# ESP32S31_RADIO register map
Vendor: Espressif; Series: ESP32-S31; File version: 3.52
Registers are 32-bit, read-write, no defined reset value unless marked. A register's access mark holds for its fields unless they carry their own. Offsets are from the block's base; [hi:lo] are bit positions; {n}, {i} and the like mark numbered series.

## PHY_BTAGC_RECOVERED — Sparse BTAGC words absent from the public platform PAC.
Base 0x20102800
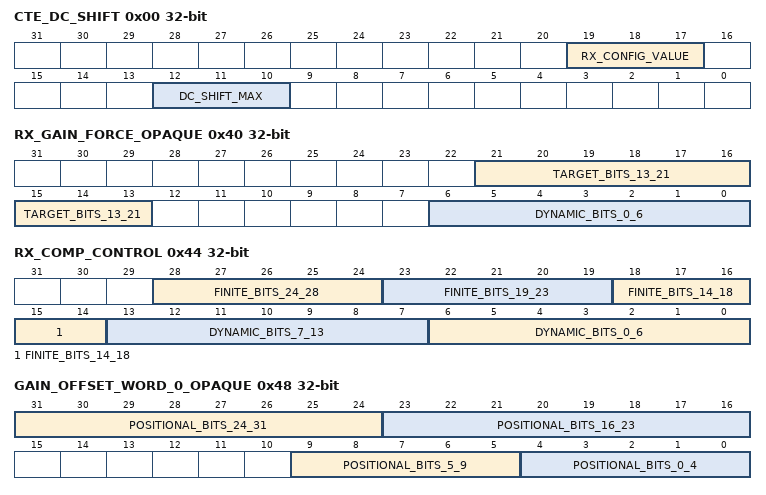
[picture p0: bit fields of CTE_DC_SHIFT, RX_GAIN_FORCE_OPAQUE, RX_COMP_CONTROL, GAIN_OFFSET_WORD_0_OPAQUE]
0x00 CTE_DC_SHIFT — Bluetooth CTE DC-shift limit control; only the independently named three-bit maximum field is assigned.
  [19:17] RX_CONFIG_VALUE — bt_bb_rx_set replaces this field with the finite value 7. No narrower hardware meaning is claimed.
  [12:10] DC_SHIFT_MAX
0x20 CTE_RE_GAIN — Bluetooth CTE receive-gain control; the setter unconditionally sets the exposed enable bit.
  [1] RE_GAIN_ENABLE
0x40 RX_GAIN_FORCE_OPAQUE — Complete phy_rx_gain_force and bt_agc_target_set read-modify-write two disjoint positional fields in this word.
  [21:13] TARGET_BITS_13_21 — bt_agc_target_set replaces this positional field with the finite image 0x1d4.
  [6:0] DYNAMIC_BITS_0_6 — bt_agc_gain_set replaces this field with the low seven bits of the byte read from the linked phy_param image at offset 0x120.
0x44 RX_COMP_CONTROL — Complete bt_set_rx_comp updates five non-overlapping fields; the two low fields are dynamic and the three higher fields receive finite images.
  [28:24] FINITE_BITS_24_28 — The leaf replaces this field with 6.
  [23:19] FINITE_BITS_19_23 — The leaf replaces this field with 0.
  [18:14] FINITE_BITS_14_18 — The leaf replaces this field with 8.
  [13:7] DYNAMIC_BITS_7_13 — The leaf replaces this exact field with a dynamic image.
  [6:0] DYNAMIC_BITS_0_6 — The leaf replaces this exact field with a dynamic image.
0x48 GAIN_OFFSET_WORD_0_OPAQUE — Complete bt_set_rx_comp and bt_agc_gain_offset read-modify-write four positional fields; individual hardware meanings remain unnamed.
  [31:24] POSITIONAL_BITS_24_31, [23:16] POSITIONAL_BITS_16_23, [9:5] POSITIONAL_BITS_5_9, [4:0] POSITIONAL_BITS_0_4
0x4C RX_CONFIG_004C — Bluetooth receive setup clears one independently observed control bit.
  [26] CONFIG_FORCE_ZERO_26
0x50 AGC_GAIN_MAX_CONTROL — Complete bt_agc_gain_max replaces bits 20:14 with one dynamic image while preserving all other bits.
  [20:14] DYNAMIC_BITS_14_20 — Exact dynamic image written by the complete leaf.
0x54 AGC_GAIN_IMAGE — Complete bt_agc_gain_set replaces one seven-bit field derived from the linked phy_param byte at offset 0x120 and preserves every other bit.
  [8:2] DYNAMIC_BITS_2_8 — Exact seven-bit image produced by subtracting five from the linked phy_param byte and retaining the low seven bits.
0x58 AGC_SAT_GAIN_IMAGE_0 wo — Complete bt_agc_sat_gain writes argument 0 as the complete register image. The dynamic image remains register-level evidence.
0x5C AGC_SAT_GAIN_IMAGE_1 wo — Complete bt_agc_sat_gain writes argument 0 as the complete register image. The dynamic image remains register-level evidence.
0x64 AGC_SAT_GAIN_CONFIG wo — Complete bt_agc_sat_gain writes the complete finite image 0x00000404.
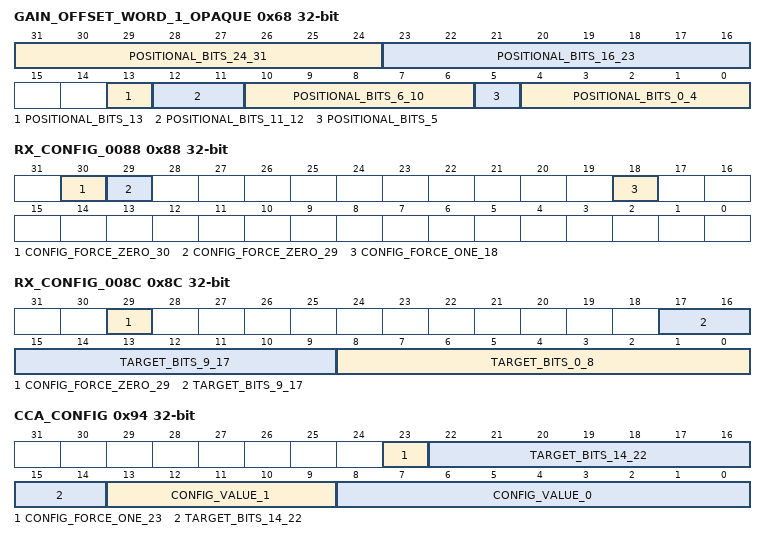
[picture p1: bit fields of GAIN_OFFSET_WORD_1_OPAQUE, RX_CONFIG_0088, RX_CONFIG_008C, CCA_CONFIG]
0x68 GAIN_OFFSET_WORD_1_OPAQUE — Complete bt_agc_gain_offset and bt_agc_recorrect_set read-modify-write seven positional fields; individual hardware meanings remain unnamed.
  [31:24] POSITIONAL_BITS_24_31, [23:16] POSITIONAL_BITS_16_23, [13] POSITIONAL_BITS_13, [12:11] POSITIONAL_BITS_11_12, [10:6] POSITIONAL_BITS_6_10, [5] POSITIONAL_BITS_5, [4:0] POSITIONAL_BITS_0_4
0x6C AGC_RECORRECT_CONTROL_006C — Complete bt_agc_recorrect_set replaces the high byte with one finite image.
  [31:24] FINITE_BITS_24_31 — The leaf replaces this field with 0x0f.
0x84 AGC_RESTART_CONFIG_0084 — Complete bt_agc_restart_set replaces the high byte with one finite image.
  [31:24] FINITE_BITS_24_31 — The leaf replaces this field with 0xf4.
0x88 RX_CONFIG_0088 — Bluetooth receive setup clears bit 29 and sets bit 18 through separate fresh-read operations.
  [30] CONFIG_FORCE_ZERO_30, [29] CONFIG_FORCE_ZERO_29, [18] CONFIG_FORCE_ONE_18
0x8C RX_CONFIG_008C — Bluetooth receive setup and target configuration update three disjoint positional fields and clear one independently observed control bit.
  [29] CONFIG_FORCE_ZERO_29
  [17:9] TARGET_BITS_9_17 — bt_agc_target_set replaces this positional field with the finite image 0x1dc.
  [8:0] TARGET_BITS_0_8 — bt_agc_target_set replaces this positional field with the finite image 0x1d4.
0x94 CCA_CONFIG — Finite Bluetooth clear-channel-assessment defaults written by bt_bb_cca_config. Untouched fields remain unassigned.
  [23] CONFIG_FORCE_ONE_23
  [22:14] TARGET_BITS_14_22 — bt_agc_target_set replaces this positional field with the finite image 0x1ce.
  [13:9] CONFIG_VALUE_1 — Five-bit finite value 0x1E.
  [8:0] CONFIG_VALUE_0 — Nine-bit finite value 0x1CE.
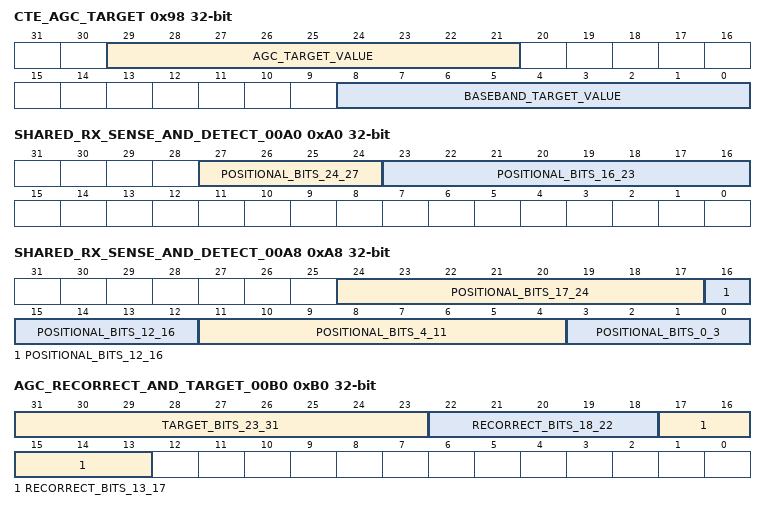
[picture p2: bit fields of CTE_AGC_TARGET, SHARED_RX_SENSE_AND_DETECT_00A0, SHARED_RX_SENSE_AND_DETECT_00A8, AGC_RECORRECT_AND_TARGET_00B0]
0x98 CTE_AGC_TARGET — Bluetooth CTE AGC target word; only the independently named nine-bit target field is assigned.
  [29:21] AGC_TARGET_VALUE
  [8:0] BASEBAND_TARGET_VALUE — bt_agc_target_set replaces this disjoint low field with the finite image 0x1d4.
0xA0 SHARED_RX_SENSE_AND_DETECT_00A0 — Complete bt_bb_set_rx_sense publishes a complete dynamic image. Independent finite RMWs replace two positional fields used by the bounded baseband initializer.
  [27:24] POSITIONAL_BITS_24_27, [23:16] POSITIONAL_BITS_16_23
0xA8 SHARED_RX_SENSE_AND_DETECT_00A8 — Complete bt_bb_set_rx_sense publishes a complete dynamic image. Independent finite RMWs replace four positional fields used by the bounded baseband initializer.
  [24:17] POSITIONAL_BITS_17_24, [16:12] POSITIONAL_BITS_12_16, [11:4] POSITIONAL_BITS_4_11, [3:0] POSITIONAL_BITS_0_3
0xB0 AGC_RECORRECT_AND_TARGET_00B0 — Finite images written by complete bt_agc_recorrect_set and bt_agc_target_set leaves.
  [31:23] TARGET_BITS_23_31 — bt_agc_target_set replaces this field with 0x1d4.
  [22:18] RECORRECT_BITS_18_22 — bt_agc_recorrect_set replaces this field with 0x18.
  [17:13] RECORRECT_BITS_13_17 — bt_agc_recorrect_set replaces this field with 0x18.
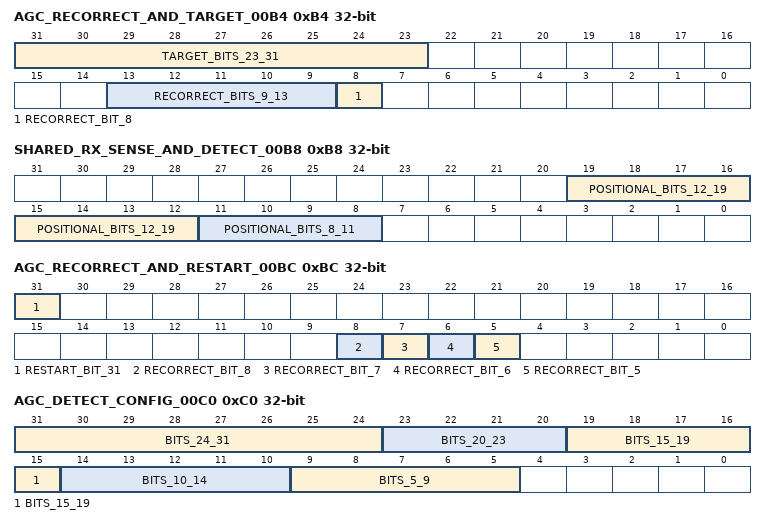
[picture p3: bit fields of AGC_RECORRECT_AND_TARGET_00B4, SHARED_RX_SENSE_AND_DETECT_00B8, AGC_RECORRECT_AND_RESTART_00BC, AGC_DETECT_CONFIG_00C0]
0xB4 AGC_RECORRECT_AND_TARGET_00B4 — Finite images written by complete bt_agc_recorrect_set and bt_agc_target_set leaves.
  [31:23] TARGET_BITS_23_31 — bt_agc_target_set replaces this field with 0x1ce.
  [13:9] RECORRECT_BITS_9_13 — bt_agc_recorrect_set replaces this field with 0x0a.
  [8] RECORRECT_BIT_8 — bt_agc_recorrect_set sets this bit.
0xB8 SHARED_RX_SENSE_AND_DETECT_00B8 — Complete bt_bb_set_rx_sense publishes a complete dynamic image. Independent finite RMWs replace two positional fields used by the bounded baseband initializer.
  [19:12] POSITIONAL_BITS_12_19, [11:8] POSITIONAL_BITS_8_11
0xBC AGC_RECORRECT_AND_RESTART_00BC — Complete recorrect and restart leaves independently update five observed control bits.
  [31] RESTART_BIT_31 — bt_agc_restart_set sets this bit.
  [8] RECORRECT_BIT_8 — bt_agc_recorrect_set clears this bit.
  [7] RECORRECT_BIT_7 — bt_agc_recorrect_set sets this bit.
  [6] RECORRECT_BIT_6 — bt_agc_recorrect_set clears this bit.
  [5] RECORRECT_BIT_5 — bt_agc_recorrect_set sets this bit.
0xC0 AGC_DETECT_CONFIG_00C0 — Complete bt_agc_detect_set replaces five positional fields with finite images.
  [31:24] BITS_24_31 — The leaf replaces this field with 0x9c.
  [23:20] BITS_20_23 — The leaf replaces this field with 7.
  [19:15] BITS_15_19 — The leaf replaces this field with 0x0a.
  [14:10] BITS_10_14 — The leaf replaces this field with 0x0a.
  [9:5] BITS_5_9 — The leaf replaces this field with 0x0a.
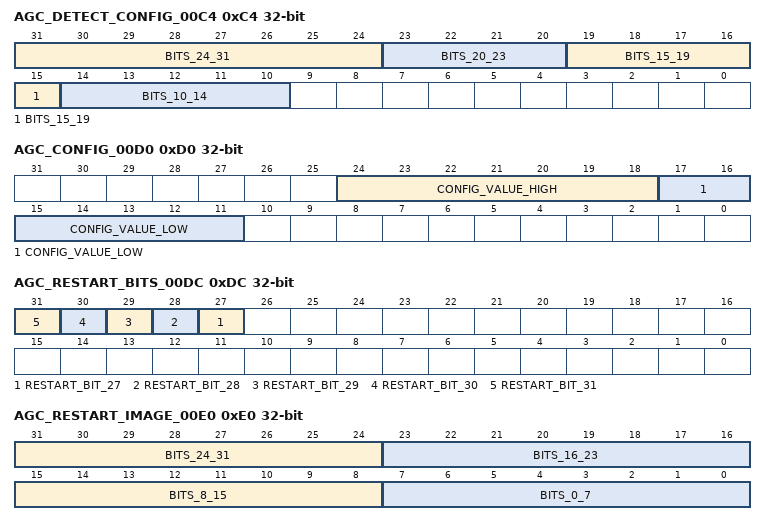
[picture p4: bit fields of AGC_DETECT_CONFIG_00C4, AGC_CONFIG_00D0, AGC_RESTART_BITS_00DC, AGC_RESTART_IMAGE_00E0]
0xC4 AGC_DETECT_CONFIG_00C4 — Complete bt_agc_detect_set replaces four positional fields with finite images.
  [31:24] BITS_24_31 — The leaf replaces this field with 0x9c.
  [23:20] BITS_20_23 — The leaf replaces this field with 0x0a.
  [19:15] BITS_15_19 — The leaf replaces this field with 0x0f.
  [14:10] BITS_10_14 — The leaf replaces this field with 0x0f.
0xD0 AGC_CONFIG_00D0 — bt_agc_v2_set replaces two seven-bit fields with the finite value 20.
  [24:18] CONFIG_VALUE_HIGH, [17:11] CONFIG_VALUE_LOW
0xD4 AGC_CONFIG_00D4 — bt_agc_v2_set replaces bits 24:6 with the finite image 0x003C0.
  [24:6] CONFIG_VALUE
0xDC AGC_RESTART_BITS_00DC — Complete bt_agc_restart_set sets five independently observed high control bits through separate fresh-read RMW operations.
  [n] RESTART_BIT_{n} (n=27..31) — The leaf sets this bit.
0xE0 AGC_RESTART_IMAGE_00E0 — Four positional byte images written by complete bt_agc_restart_set.
  [31:24] BITS_24_31 — The leaf replaces this field with 0x14.
  [23:16] BITS_16_23 — The leaf replaces this field with 0x0e.
  [15:8] BITS_8_15 — The leaf replaces this field with 0x0e.
  [7:0] BITS_0_7 — The leaf replaces this field with 0x0f.
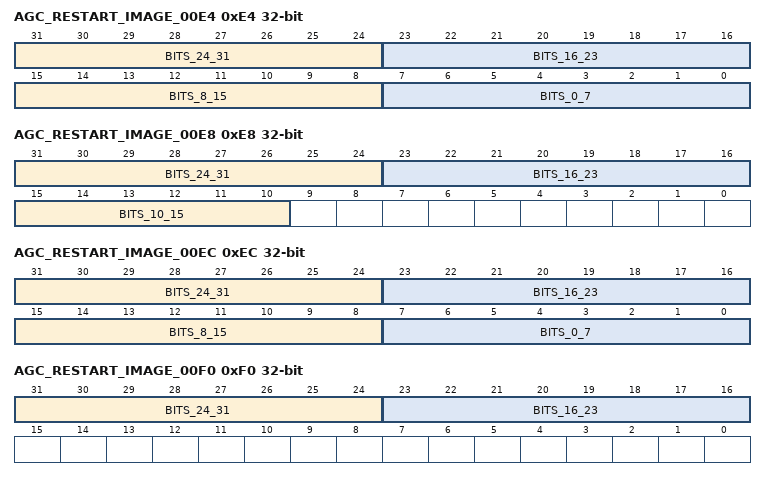
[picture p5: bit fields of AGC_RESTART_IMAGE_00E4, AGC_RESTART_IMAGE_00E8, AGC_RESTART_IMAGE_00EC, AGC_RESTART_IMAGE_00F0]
0xE4 AGC_RESTART_IMAGE_00E4 — Four positional byte images written by complete bt_agc_restart_set.
  [31:24] BITS_24_31 — The leaf replaces this field with 0x1e.
  [23:16] BITS_16_23 — The leaf replaces this field with 0xec.
  [15:8] BITS_8_15 — The leaf replaces this field with 0xf2.
  [7:0] BITS_0_7 — The leaf replaces this field with 0xf2.
0xE8 AGC_RESTART_IMAGE_00E8 — Three positional finite images written by complete bt_agc_restart_set; bits 9:0 remain unassigned.
  [31:24] BITS_24_31 — The leaf replaces this field with 0xf1.
  [23:16] BITS_16_23 — The leaf replaces this field with 0xe2.
  [15:10] BITS_10_15 — The leaf replaces this field with 3.
0xEC AGC_RESTART_IMAGE_00EC — Four positional byte images written by complete bt_agc_restart_set.
  [31:24] BITS_24_31 — The leaf replaces this field with 0x2d.
  [23:16] BITS_16_23 — The leaf replaces this field with 0x28.
  [15:8] BITS_8_15 — The leaf replaces this field with 0xd3.
  [7:0] BITS_0_7 — The leaf replaces this field with 0xd8.
0xF0 AGC_RESTART_IMAGE_00F0 — Two positional high-byte images written by complete bt_agc_restart_set; bits 15:0 remain unassigned.
  [31:24] BITS_24_31 — The leaf replaces this field with 0xa6.
  [23:16] BITS_16_23 — The leaf replaces this field with 0xa6.
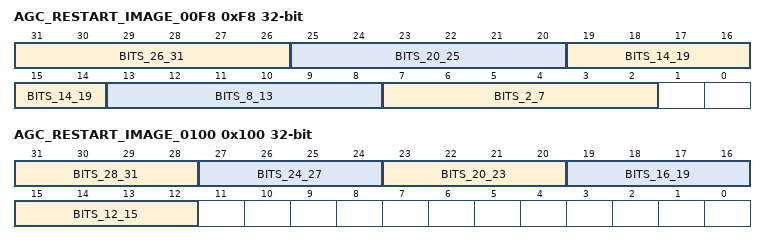
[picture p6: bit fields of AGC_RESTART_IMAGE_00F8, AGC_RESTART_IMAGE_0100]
0xF8 AGC_RESTART_IMAGE_00F8 — Five positional six-bit images written by complete bt_agc_restart_set; bits 1:0 remain unassigned.
  [31:26] BITS_26_31 — The leaf replaces this field with 0x0c.
  [25:20] BITS_20_25 — The leaf replaces this field with 5.
  [19:14] BITS_14_19 — The leaf replaces this field with 0x20.
  [13:8] BITS_8_13 — The leaf replaces this field with 0x0c.
  [7:2] BITS_2_7 — The leaf replaces this field with 0x0c.
0x100 AGC_RESTART_IMAGE_0100 — Five positional high-nibble images written by complete bt_agc_restart_set; bits 11:0 remain unassigned.
  [31:28] BITS_28_31 — The leaf replaces this field with 6.
  [27:24] BITS_24_27 — The leaf replaces this field with 6.
  [23:20] BITS_20_23 — The leaf replaces this field with 6.
  [19:16] BITS_16_19 — The leaf replaces this field with 8.
  [15:12] BITS_12_15 — The leaf replaces this field with 0x0a.
